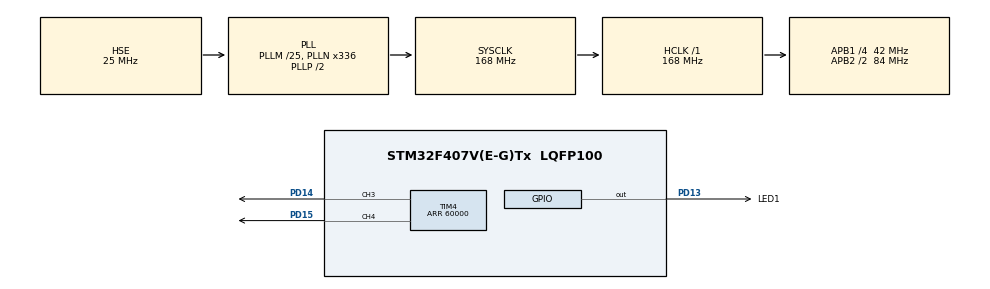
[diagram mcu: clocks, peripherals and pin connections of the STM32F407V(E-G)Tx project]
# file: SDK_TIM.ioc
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Mcu.Family=STM32F4
Mcu.Name=STM32F407V(E-G)Tx
Mcu.Package=LQFP100
NVIC.PriorityGroup=NVIC_PRIORITYGROUP_4
NVIC.TIM7_IRQn=true\:0\:0\:false\:false\:true\:true\:true
PA13.Mode=JTAG_5_pins
PA13.Signal=SYS_JTMS-SWDIO
PA14.Mode=JTAG_5_pins
PA14.Signal=SYS_JTCK-SWCLK
PA15.Mode=JTAG_5_pins
PA15.Signal=SYS_JTDI
PB3.Mode=JTAG_5_pins
PB3.Signal=SYS_JTDO-SWO
PB4.Mode=JTAG_5_pins
PB4.Signal=SYS_JTRST
PD13.GPIO_Label=LED1
PD13.Signal=GPIO_Output
PD14.GPIO_ModeDefaultPP=GPIO_MODE_AF_PP
PD14.GPIO_PuPd=GPIO_NOPULL
PD14.GPIO_Speed=GPIO_SPEED_FREQ_HIGH
PD14.Signal=S_TIM4_CH3
PD15.GPIO_ModeDefaultPP=GPIO_MODE_AF_PP
PD15.GPIO_PuPd=GPIO_NOPULL
PD15.GPIO_Speed=GPIO_SPEED_FREQ_HIGH
PD15.Signal=S_TIM4_CH4
PH0-OSC_IN.Mode=HSE-External-Oscillator
PH0-OSC_IN.Signal=RCC_OSC_IN
PH1-OSC_OUT.Mode=HSE-External-Oscillator
PH1-OSC_OUT.Signal=RCC_OSC_OUT
ProjectManager.HeapSize=0x200
ProjectManager.StackSize=0x400
ProjectManager.TargetToolchain=STM32CubeIDE
RCC.48MHZClocksFreq_Value=84000000
RCC.AHBFreq_Value=168000000
RCC.APB1CLKDivider=RCC_HCLK_DIV4
RCC.APB1Freq_Value=42000000
RCC.APB1TimFreq_Value=84000000
RCC.APB2CLKDivider=RCC_HCLK_DIV2
RCC.APB2Freq_Value=84000000
RCC.APB2TimFreq_Value=168000000
RCC.CortexFreq_Value=168000000
RCC.HCLKFreq_Value=168000000
RCC.HSE_VALUE=25000000
RCC.HSI_VALUE=16000000
RCC.LSE_VALUE=32768
RCC.PLLM=25
RCC.PLLN=336
RCC.PLLSourceVirtual=RCC_PLLSOURCE_HSE
RCC.SYSCLKFreq_VALUE=168000000
RCC.SYSCLKSource=RCC_SYSCLKSOURCE_PLLCLK
RCC.VCOOutputFreq_Value=336000000
SH.S_TIM4_CH3.0=TIM4_CH3,PWM Generation3 CH3
SH.S_TIM4_CH4.0=TIM4_CH4,PWM Generation4 CH4
TIM4.Channel-PWM\ Generation3\ CH3=TIM_CHANNEL_3
TIM4.Channel-PWM\ Generation4\ CH4=TIM_CHANNEL_4
TIM4.Period=60000
TIM7.Period=10000
TIM7.Prescaler=16799
TIM7.TIM_MasterOutputTrigger=TIM_TRGO_UPDATE
VP_TIM4_VS_ClockSourceINT.Mode=Internal
VP_TIM7_VS_ClockSourceINT.Mode=Enable_Timer
board=custom

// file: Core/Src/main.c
/* USER CODE BEGIN Header */
/**
  ******************************************************************************
  * @file           : main.c
  * @brief          : Main program body
  ******************************************************************************
  * @attention
  *
  * <h2><center>&copy; Copyright (c) 2020 STMicroelectronics.
  * All rights reserved.</center></h2>
  *
  * This software component is licensed by ST under BSD 3-Clause license,
  * the "License"; You may not use this file except in compliance with the
  * License. You may obtain a copy of the License at:
  *                        opensource.org/licenses/BSD-3-Clause
  *
  ******************************************************************************
  */
/* USER CODE END Header */

#include "main.h"
#include "tim.h"
#include "gpio.h"

void SystemClock_Config(void);
/* USER CODE BEGIN PFP */
void PWM_LED (void);
/* USER CODE END PFP */

int main(void)
{

  /* MCU Configuration--------------------------------------------------------*/

  /* Reset of all peripherals, Initializes the Flash interface and the Systick. */
  HAL_Init();

  /* Configure the system clock */
  SystemClock_Config();

  /* Initialize all configured peripherals */
  MX_GPIO_Init();
  MX_TIM4_Init();
  MX_TIM7_Init();
  /* USER CODE BEGIN 2 */
  HAL_TIM_OC_Start(&htim4,TIM_CHANNEL_3);
  HAL_TIM_OC_Start(&htim4,TIM_CHANNEL_4);
  HAL_TIM_PWM_Init(&htim4);
  HAL_TIM_PWM_Start(&htim4, TIM_CHANNEL_3);
  HAL_TIM_PWM_Start(&htim4, TIM_CHANNEL_4);
  HAL_TIM_Base_Start_IT(&htim7);
  /* USER CODE END 2 */

  /* Infinite loop */
  while (1)
  {

    /* USER CODE BEGIN 3 */
	  PWM_LED();
  }
  /* USER CODE END 3 */
}

void SystemClock_Config(void)
{
  RCC_OscInitTypeDef RCC_OscInitStruct = {0};
  RCC_ClkInitTypeDef RCC_ClkInitStruct = {0};

  /** Configure the main internal regulator output voltage
  */
  __HAL_RCC_PWR_CLK_ENABLE();
  __HAL_PWR_VOLTAGESCALING_CONFIG(PWR_REGULATOR_VOLTAGE_SCALE1);
  /** Initializes the CPU, AHB and APB busses clocks
  */
  RCC_OscInitStruct.OscillatorType = RCC_OSCILLATORTYPE_HSE;
  RCC_OscInitStruct.HSEState = RCC_HSE_ON;
  RCC_OscInitStruct.PLL.PLLState = RCC_PLL_ON;
  RCC_OscInitStruct.PLL.PLLSource = RCC_PLLSOURCE_HSE;
  RCC_OscInitStruct.PLL.PLLM = 25;
  RCC_OscInitStruct.PLL.PLLN = 336;
  RCC_OscInitStruct.PLL.PLLP = RCC_PLLP_DIV2;
  RCC_OscInitStruct.PLL.PLLQ = 4;
  if (HAL_RCC_OscConfig(&RCC_OscInitStruct) != HAL_OK)
  {
    Error_Handler();
  }
  /** Initializes the CPU, AHB and APB busses clocks
  */
  RCC_ClkInitStruct.ClockType = RCC_CLOCKTYPE_HCLK|RCC_CLOCKTYPE_SYSCLK
                              |RCC_CLOCKTYPE_PCLK1|RCC_CLOCKTYPE_PCLK2;
  RCC_ClkInitStruct.SYSCLKSource = RCC_SYSCLKSOURCE_PLLCLK;
  RCC_ClkInitStruct.AHBCLKDivider = RCC_SYSCLK_DIV1;
  RCC_ClkInitStruct.APB1CLKDivider = RCC_HCLK_DIV4;
  RCC_ClkInitStruct.APB2CLKDivider = RCC_HCLK_DIV2;

  if (HAL_RCC_ClockConfig(&RCC_ClkInitStruct, FLASH_LATENCY_5) != HAL_OK)
  {
    Error_Handler();
  }
}

/* USER CODE BEGIN 4 */
//Плавное зажигание светодиодов
void PWM_LED (void) {
	for (int i = 0; i < 240001; i+=100) {
		if (i < 60001)
			TIM4->CCR3 = i;
		else if ((i > 60000) && (i < 120100))
			TIM4->CCR3 = 120100 - i;
		else if ((i > 12000) && (i < 180100))
			TIM4->CCR4 = i - 120000;
		else
			TIM4->CCR4 = 240000 - i;
	HAL_Delay(1);
	}
}
//Если сработало прерывание от TIM7, то вызывается Callback
void HAL_TIM_PeriodElapsedCallback(TIM_HandleTypeDef *htim) {
	if (htim == &htim7) HAL_GPIO_TogglePin(GPIOD, GPIO_PIN_13);
}

/* USER CODE END 4 */

void Error_Handler(void)
{
}

/************************ (C) COPYRIGHT STMicroelectronics *****END OF FILE****/
